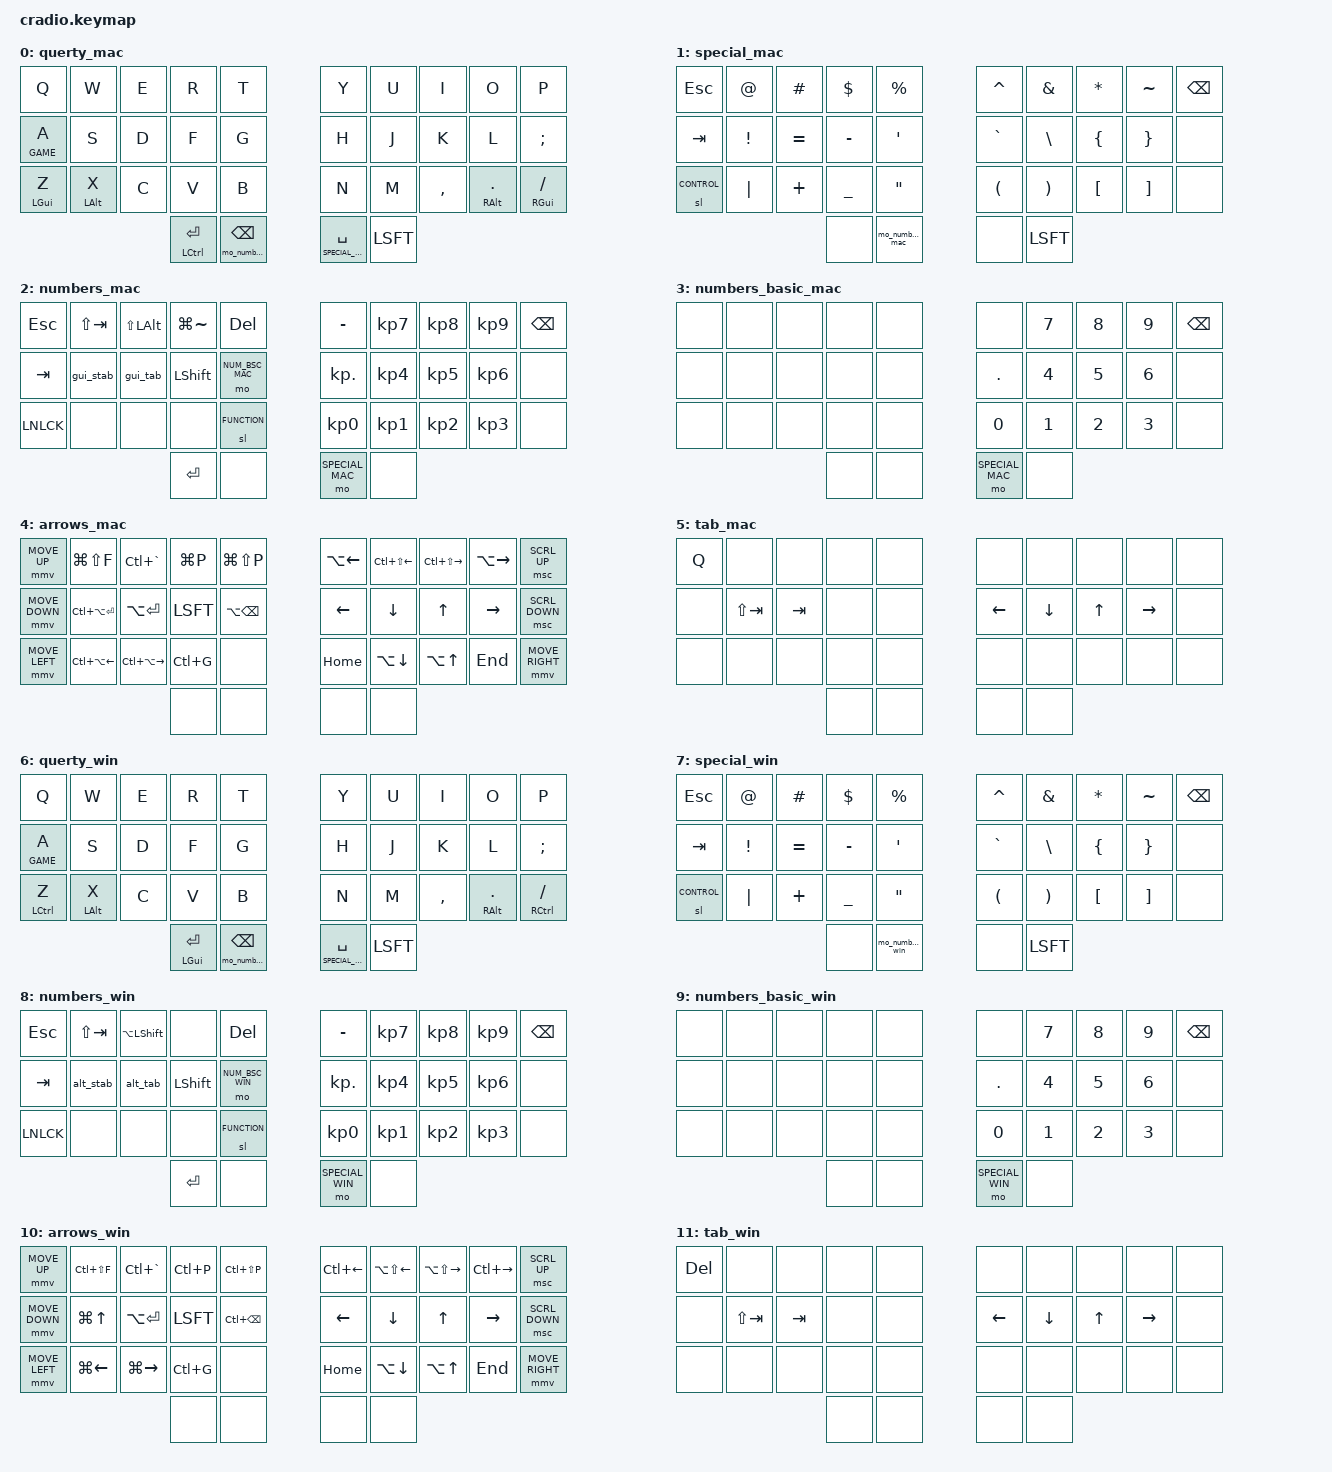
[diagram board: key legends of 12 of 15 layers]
/*
 * Copyright (c) 2020 The ZMK Contributors
 *
 * SPDX-License-Identifier: MIT
 */

#undef ZMK_BEHAVIORS_KEEP_ALL

#include <behaviors.dtsi>
#include <dt-bindings/zmk/keys.h>
#include <dt-bindings/zmk/bt.h>

#define ZMK_POINTING_DEFAULT_MOVE_VAL 1500  // default: 600
#define ZMK_POINTING_DEFAULT_SCRL_VAL 20    // default: 10

#include <dt-bindings/zmk/pointing.h>


#define QUERTY_MAC 0
#define SPECIAL_MAC 1
#define NUMBERS_MAC 2
#define NUM_BSC_MAC 3
#define ARROWS_MAC 4
#define TAB_MAC 5


#define QUERTY_WIN 6
#define SPECIAL_WIN 7
#define NUMBERS_WIN 8
#define NUM_BSC_WIN 9
#define ARROWS_WIN 10
#define TAB_WIN 11

#define CONTROL 12
#define GAME 13
#define FUNCTION 14


#define _______ &none

&sl {
    release-after-ms = <3000>;
};


/ {
    behaviors {
        // tap preferred variants of the lt and mt
        mtt: mtt {
            compatible = "zmk,behavior-hold-tap";
            #binding-cells = <2>;
            flavor = "tap-preferred";
            tapping-term-ms = <200>;
            bindings = <&kp>, <&kp>;
            display-name = "Layer-Tap";
        };

        ltt: ltt {
            compatible = "zmk,behavior-hold-tap";
            #binding-cells = <2>;
            flavor = "tap-preferred";
            tapping-term-ms = <200>;
            bindings = <&mo>, <&kp>;
            display-name = "Layer-Tap";
        };

        // use below with a dummy value for first parameter: &lt_numbers_mac 0 BSPC
        lt_numbers_mac: lt_numbers_mac {
            compatible = "zmk,behavior-hold-tap";
            label = "lt_numbers_mac";
            #binding-cells = <2>;
            flavor = "hold-preferred";
            tapping-term-ms = <200>;
            bindings = <&mo_numbers_mac>, <&kp>;
        };

        lt_numbers_win: lt_numbers_win {
            compatible = "zmk,behavior-hold-tap";
            label = "lt_numbers_win";
            #binding-cells = <2>;
            flavor = "hold-preferred";
            tapping-term-ms = <200>;
            bindings = <&mo_numbers_win>, <&kp>;
        };

        tog_off: tog_off {
            compatible = "zmk,behavior-toggle-layer";
            #binding-cells = <1>;
            display-name = "Toggle Layer Off";
            toggle-mode = "off";
        };

        tog_on: tog_on {
            compatible = "zmk,behavior-toggle-layer";
            #binding-cells = <1>;
            display-name = "Toggle Layer On";
            toggle-mode = "on";
        };
    };

    macros {
        gui_tab: gui_tab {
            compatible = "zmk,behavior-macro";
            #binding-cells = <0>;
            bindings
                = <&macro_press &kp LGUI>
                , <&macro_tap &kp TAB>
                , <&tog_on TAB_MAC>;
        };

        gui_stab: gui_stab {
            compatible = "zmk,behavior-macro";
            #binding-cells = <0>;
            bindings
                = <&macro_press &kp LGUI>
                , <&macro_tap &kp LS(TAB)>
                , <&tog_on TAB_MAC>;
        };

        alt_tab: alt_tab {
            compatible = "zmk,behavior-macro";
            #binding-cells = <0>;
            bindings
                = <&macro_press &kp LALT>
                , <&macro_tap &kp TAB>
                , <&tog_on TAB_WIN>;
        };

        alt_stab: alt_stab {
            compatible = "zmk,behavior-macro";
            #binding-cells = <0>;
            bindings
                = <&macro_press &kp LALT>
                , <&macro_tap &kp LS(TAB)>
                , <&tog_on TAB_WIN>;
        };

        // momentary numbers layer switching macro
        mo_numbers_mac: mo_numbers_mac {
            compatible = "zmk,behavior-macro";
            label = "mo_numbers_mac";
            #binding-cells = <0>;
            wait-ms = <0>;
            tap-ms = <0>;
            bindings = <&macro_press &tog_on NUMBERS_MAC>
                    , <&macro_pause_for_release>
                    , <&macro_release &kp LGUI>
                    , <&macro_press &tog_off NUMBERS_MAC>
                    , <&macro_press &tog_off TAB_MAC>
                    , <&macro_press &tog_off NUM_BSC_MAC>;
        };

        mo_numbers_win: mo_numbers_win {
            compatible = "zmk,behavior-macro";
            label = "mo_numbers_win";
            #binding-cells = <0>;
            wait-ms = <0>;
            tap-ms = <0>;
            bindings = <&macro_press &tog_on NUMBERS_WIN>
                    , <&macro_pause_for_release>
                    , <&macro_release &kp LALT>
                    , <&macro_press &tog_off NUMBERS_WIN>
                    , <&macro_press &tog_off TAB_WIN>
                    , <&macro_press &tog_off NUM_BSC_WIN>;
        };
    };

    conditional_layers {
        compatible = "zmk,conditional-layers";
        arrows_mac {
            if-layers = <SPECIAL_MAC NUMBERS_MAC>;
            then-layer = <ARROWS_MAC>;
        };
        arrows_win {
            if-layers = <SPECIAL_WIN NUMBERS_WIN>;
            then-layer = <ARROWS_WIN>;
        };
    };

    keymap {
        compatible = "zmk,keymap";

        //
        // MAC
        //

        querty_mac {    
            // todo add game switch layer
            bindings = <
                &kp Q        &kp W       &kp E     &kp R     &kp T                &kp Y     &kp U     &kp I      &kp O          &kp P 
                &ltt GAME A  &kp S       &kp D     &kp F     &kp G                &kp H     &kp J     &kp K      &kp L          &kp SCLN 
                &mt LGUI Z   &mtt LALT X &kp C     &kp V     &kp B                &kp N     &kp M     &kp COMMA  &mtt RALT DOT  &mt RGUI FSLH 
                            &mt LCTRL RET      &lt_numbers_mac 0 BSPC         &lt SPECIAL_MAC SPACE      &kp LSFT
            >;
        };

        special_mac {
            bindings = <
                &kp ESC     &kp AT   &kp HASH   &kp DLLR  &kp PERCENT      &kp CARET  &kp AMPS &kp ASTRK &kp TILDE &kp BSPC
                &kp TAB     &kp EXCL &kp EQUAL  &kp MINUS &kp SQT          &kp GRAVE  &kp BSLH &kp LBRC  &kp RBRC  _______
                &sl CONTROL &kp PIPE &kp PLUS   &kp UNDER &kp DQT          &kp LPAR   &kp RPAR &kp LBKT  &kp RBKT  _______
                                _______     &mo_numbers_mac             _______   &kp LSFT
            >;
        };

        numbers_mac {
            bindings = <
                &kp ESC   &kp LS(TAB) &kp LS(LALT) &kp LG(TILDE)   &kp DEL              &kp MINUS      &kp KP_N7    &kp KP_N8    &kp KP_N9    &kp BSPC
                &kp TAB   &gui_stab   &gui_tab     &kp LSHIFT      &mo NUM_BSC_MAC      &kp KP_DOT     &kp KP_N4    &kp KP_N5    &kp KP_N6    _______
                &kp LNLCK _______     _______      _______         &sl FUNCTION         &kp KP_N0      &kp KP_N1    &kp KP_N2    &kp KP_N3    _______
                                                 &kp RET         _______              &mo SPECIAL_MAC _______
            >;
        };

        numbers_basic_mac {
            bindings = <
                _______   _______  _______  _______  _______          _______  &kp N7  &kp N8  &kp N9 &kp BSPC
                _______   _______  _______  _______  _______          &kp DOT  &kp N4  &kp N5  &kp N6 _______
                _______   _______  _______  _______  _______          &kp N0   &kp N1  &kp N2  &kp N3 _______
                                             _______   _______        &mo SPECIAL_MAC _______
            >;
        };

        arrows_mac {
            bindings = <
                /* mouse up      find in project   open terminal      find file   command palete         skip left     back             forward        skip right        mouse scroll up*/
                &mmv MOVE_UP     &kp LG(LS(F))     &kp LC(GRAVE)       &kp LG(P)   &kp LG(LS(P))          &kp LA(LEFT) &kp LC(LS(LEFT)) &kp LC(LS(RIGHT))  &kp LA(RIGHT) &msc SCRL_UP
                /* mouse down    maximise          cursors to ref      select word     delete word            ---------------------arrows---------------------------     mouse scroll down*/
                &mmv MOVE_DOWN   &kp LC(LA(RET))   &kp LA(RET)         &kp LSFT    &kp LA(BSPC)           &kp LEFT     &kp DOWN         &kp UP             &kp RIGHT     &msc SCRL_DOWN
                /* mouse left    dock left         dock right          go to line                          start line   move down        move up           end line      mouse right*/
                &mmv MOVE_LEFT   &kp LC(LA(LEFT))  &kp LC(LA(RIGHT))   &kp LC(G)     _______              &kp HOME     &kp LA(DOWN)     &kp LA(UP)         &kp END       &mmv MOVE_RIGHT
                                                                        _______     _______                  _______      _______
            >;
        };

        tab_mac {
            bindings = <
                &kp Q     _______      _______       _______  _______          _______ _______      _______      _______      _______
                _______   &kp LS(TAB)  &kp TAB       _______  _______         &kp LEFT &kp DOWN     &kp UP       &kp RIGHT    _______
                _______   _______      _______       _______  _______          _______ _______      _______      _______      _______
                                       _______       _______                _______ _______
            >;
        };

        //
        // WINDOWS
        //

        querty_win {    
            // todo add game switch layer
            bindings = <
                &kp Q        &kp W       &kp E     &kp R     &kp T                &kp Y     &kp U     &kp I      &kp O          &kp P 
                &ltt GAME A  &kp S       &kp D     &kp F     &kp G                &kp H     &kp J     &kp K      &kp L          &kp SCLN 
                &mt LCTRL Z  &mtt LALT X &kp C     &kp V     &kp B                &kp N     &kp M     &kp COMMA  &mtt RALT DOT  &mt RCTRL FSLH 
                            &mt LGUI RET      &lt_numbers_win 0 BSPC         &lt SPECIAL_WIN SPACE      &kp LSFT
            >;
        };

        special_win {
            bindings = <
                &kp ESC     &kp AT   &kp HASH   &kp DLLR  &kp PERCENT      &kp CARET  &kp AMPS &kp ASTRK &kp TILDE &kp BSPC
                &kp TAB     &kp EXCL &kp EQUAL  &kp MINUS &kp SQT          &kp GRAVE  &kp BSLH &kp LBRC  &kp RBRC  _______
                &sl CONTROL &kp PIPE &kp PLUS   &kp UNDER &kp DQT          &kp LPAR   &kp RPAR &kp LBKT  &kp RBKT  _______
                                _______     &mo_numbers_win             _______   &kp LSFT
            >;
        };

        numbers_win {
            bindings = <
                &kp ESC   &kp LS(TAB) &kp LA(LSHIFT) _______     &kp DEL               &kp MINUS      &kp KP_N7    &kp KP_N8    &kp KP_N9    &kp BSPC
                &kp TAB   &alt_stab   &alt_tab       &kp LSHIFT  &mo NUM_BSC_WIN       &kp KP_DOT     &kp KP_N4    &kp KP_N5    &kp KP_N6    _______
                &kp LNLCK _______     _______        _______     &sl FUNCTION          &kp KP_N0      &kp KP_N1    &kp KP_N2    &kp KP_N3    _______
                                                   &kp RET     _______               &mo SPECIAL_WIN _______
            >;
        };

        numbers_basic_win {
            bindings = <
                _______   _______  _______  _______  _______          _______  &kp N7  &kp N8  &kp N9 &kp BSPC
                _______   _______  _______  _______  _______          &kp DOT  &kp N4  &kp N5  &kp N6 _______
                _______   _______  _______  _______  _______          &kp N0   &kp N1  &kp N2  &kp N3 _______
                                             _______   _______        &mo SPECIAL_WIN _______
            >;
        };

        arrows_win {
            bindings = <
                /* mouse up      find in project   open terminal      find file   command palete         skip left     back             forward        skip right        mouse scroll up*/
                &mmv MOVE_UP     &kp LC(LS(F))     &kp LC(GRAVE)       &kp LC(P)   &kp LC(LS(P))          &kp LC(LEFT) &kp LA(LS(LEFT)) &kp LA(LS(RIGHT))  &kp LC(RIGHT) &msc SCRL_UP
                /* mouse down    maximise          cursors to ref      select word     delete word            ---------------------arrows---------------------------     mouse scroll down*/
                &mmv MOVE_DOWN   &kp LG(UP)        &kp LA(RET)         &kp LSFT    &kp LC(BSPC)           &kp LEFT     &kp DOWN         &kp UP             &kp RIGHT     &msc SCRL_DOWN
                /* mouse left    dock left         dock right          go to line                         start line   move down        move up           end line       mouse right*/
                &mmv MOVE_LEFT   &kp LG(LEFT)      &kp LG(RIGHT)       &kp LC(G)   _______                &kp HOME     &kp LA(DOWN)     &kp LA(UP)         &kp END       &mmv MOVE_RIGHT
                                                                        _______     _______                  _______      _______
            >;
        };

        tab_win {
            bindings = <
                &kp DEL   _______      _______       _______  _______          _______ _______      _______      _______      _______
                _______   &kp LS(TAB)  &kp TAB       _______  _______         &kp LEFT &kp DOWN     &kp UP       &kp RIGHT    _______
                _______   _______      _______       _______  _______          _______ _______      _______      _______      _______
                                                     _______  _______          _______ _______
            >;
        };

        control {
            bindings = <
                _______         &bt BT_CLR_ALL  &bt BT_CLR _______  _______          _______ _______         _______        _______          _______
                _______         _______         _______    _______  _______          _______ &bt BT_DISC 0   &bt BT_DISC 1  &bt BT_DISC 2    _______
                &to QUERTY_WIN  &to QUERTY_MAC  _______    _______  _______          _______ &bt BT_SEL  0   &bt BT_SEL  1  &bt BT_SEL  2    _______
                                                         _______   _______              _______ _______
            >;
        };

        game {
            bindings = <
                _______   &kp Q      &kp W       &kp E        &kp R          _______ _______      _______      _______      _______
                _______   &kp A      &kp S       &kp D        &kp F          _______ _______      _______      _______      _______
                _______   _______      _______   &kp C        &kp V          _______ _______      _______      _______      _______
                                               _______   &kp SPACE                _______ _______
            >;
        };

        function {
            bindings = <
                _______   _______  _______  _______  _______          _______  &kp F7  &kp F8  &kp F9 &kp F12
                _______   _______  _______  _______  _______          _______  &kp F4  &kp F5  &kp F6 &kp F11
                _______   _______  _______  _______  _______          _______  &kp F1  &kp F2  &kp F3 &kp F10
                                               _______   _______                _______ _______
            >;
        };
    };
};
